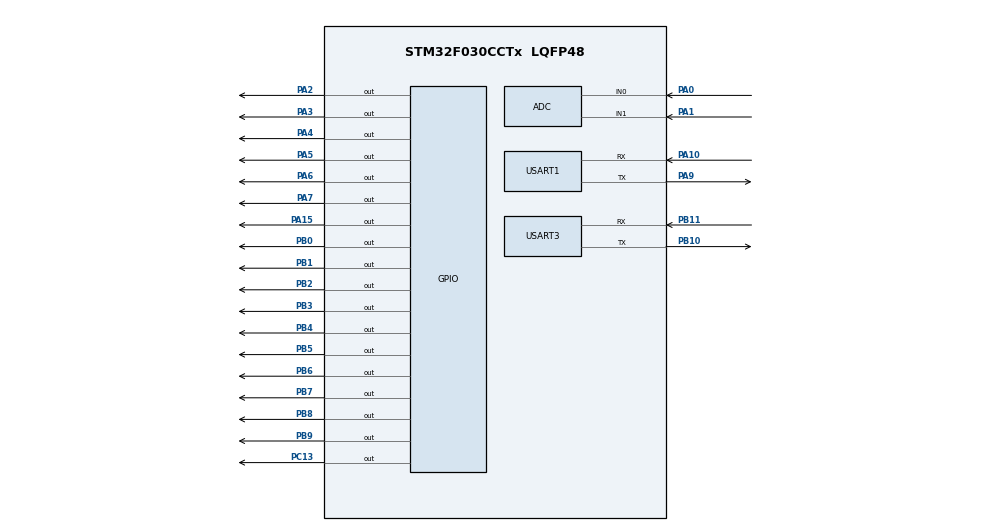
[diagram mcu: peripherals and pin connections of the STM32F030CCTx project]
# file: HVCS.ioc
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Mcu.Family=STM32F0
Mcu.Name=STM32F030CCTx
Mcu.Package=LQFP48
NVIC.ADC1_IRQn=true\:0\:0\:false\:false\:true\:true\:true\:true
NVIC.USART1_IRQn=true\:0\:0\:false\:false\:true\:true\:true\:true
NVIC.USART3_6_IRQn=true\:0\:0\:false\:false\:true\:true\:true\:true
PA0.Mode=IN0
PA0.Signal=ADC_IN0
PA1.Mode=IN1
PA1.Signal=ADC_IN1
PA10.Mode=Asynchronous
PA10.Signal=USART1_RX
PA13.Mode=Serial_Wire
PA13.Signal=SYS_SWDIO
PA14.Mode=Serial_Wire
PA14.Signal=SYS_SWCLK
PA15.Signal=GPIO_Output
PA2.Signal=GPIO_Output
PA3.Signal=GPIO_Output
PA4.Signal=GPIO_Output
PA5.Signal=GPIO_Output
PA6.Signal=GPIO_Output
PA7.Signal=GPIO_Output
PA9.Mode=Asynchronous
PA9.Signal=USART1_TX
PB0.Signal=GPIO_Output
PB1.Signal=GPIO_Output
PB10.Mode=Asynchronous
PB10.Signal=USART3_TX
PB11.Mode=Asynchronous
PB11.Signal=USART3_RX
PB2.Signal=GPIO_Output
PB3.Signal=GPIO_Output
PB4.Signal=GPIO_Output
PB5.Signal=GPIO_Output
PB6.Signal=GPIO_Output
PB7.Signal=GPIO_Output
PB8.Signal=GPIO_Output
PB9.Signal=GPIO_Output
PC13.Signal=GPIO_Output
PF0-OSC_IN.Mode=HSE-External-Oscillator
PF0-OSC_IN.Signal=RCC_OSC_IN
PF1-OSC_OUT.Mode=HSE-External-Oscillator
PF1-OSC_OUT.Signal=RCC_OSC_OUT
ProjectManager.HeapSize=0x200
ProjectManager.StackSize=0x400
ProjectManager.TargetToolchain=CMake
RCC.AHBFreq_Value=32000000
RCC.APB1Freq_Value=32000000
RCC.APB1TimFreq_Value=32000000
RCC.HCLKFreq_Value=32000000
RCC.PLLMUL=RCC_PLL_MUL4
RCC.PLLSourceVirtual=RCC_PLLSOURCE_HSE
RCC.SYSCLKFreq_VALUE=32000000
RCC.SYSCLKSource=RCC_SYSCLKSOURCE_PLLCLK
USART1.VirtualMode-Asynchronous=VM_ASYNC
USART3.VirtualMode-Asynchronous=VM_ASYNC
board=custom

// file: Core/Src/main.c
/* USER CODE BEGIN Header */
/**
  ******************************************************************************
  * @file           : main.c
  * @brief          : Main program body
  ******************************************************************************
  * @attention
  *
  * Copyright (c) 2025 STMicroelectronics.
  * All rights reserved.
  *
  * This software is licensed under terms that can be found in the LICENSE file
  * in the root directory of this software component.
  * If no LICENSE file comes with this software, it is provided AS-IS.
  *
  ******************************************************************************
  */
/* USER CODE END Header */
#include "main.h"

/* USER CODE BEGIN Includes */
#include "app.h"
/* USER CODE END Includes */

void SystemClock_Config(void);
static void MX_GPIO_Init(void);
static void MX_ADC_Init(void);
static void MX_USART1_UART_Init(void);
static void MX_USART3_UART_Init(void);

int main(void)
{

  /* MCU Configuration--------------------------------------------------------*/

  /* Reset of all peripherals, Initializes the Flash interface and the Systick. */
  LL_APB1_GRP2_EnableClock(LL_APB1_GRP2_PERIPH_SYSCFG);
  LL_APB1_GRP1_EnableClock(LL_APB1_GRP1_PERIPH_PWR);

  /* SysTick_IRQn interrupt configuration */
  NVIC_SetPriority(SysTick_IRQn, 3);

  /* Configure the system clock */
  SystemClock_Config();

  /* Initialize all configured peripherals */
  MX_GPIO_Init();
  MX_ADC_Init();
  MX_USART1_UART_Init();
  MX_USART3_UART_Init();
  /* USER CODE BEGIN 2 */
  LL_GPIO_SetOutputPin(V_DIV1_PORT, v_DIV1_PIN);
  LL_GPIO_SetOutputPin(V_DIV2_PORT, v_DIV2_PIN);
  LL_GPIO_SetOutputPin(V_DIV3_PORT, v_DIV3_PIN);
  LL_GPIO_SetOutputPin(V_DIV4_PORT, v_DIV4_PIN);

  App_Main();
  /* USER CODE END 2 */

  /* Infinite loop */
  while (1)
  {

  }
}

void SystemClock_Config(void)
{
  LL_FLASH_SetLatency(LL_FLASH_LATENCY_1);
  while(LL_FLASH_GetLatency() != LL_FLASH_LATENCY_1)
  {
  }
  LL_RCC_HSE_Enable();

   /* Wait till HSE is ready */
  while(LL_RCC_HSE_IsReady() != 1)
  {

  }
  LL_RCC_HSI14_Enable();

   /* Wait till HSI14 is ready */
  while(LL_RCC_HSI14_IsReady() != 1)
  {

  }
  LL_RCC_HSI14_SetCalibTrimming(16);
  LL_RCC_PLL_ConfigDomain_SYS(LL_RCC_PLLSOURCE_HSE, LL_RCC_PLL_MUL_4, LL_RCC_PREDIV_DIV_1);
  LL_RCC_PLL_Enable();

   /* Wait till PLL is ready */
  while(LL_RCC_PLL_IsReady() != 1)
  {

  }
  LL_RCC_SetAHBPrescaler(LL_RCC_SYSCLK_DIV_1);
  LL_RCC_SetAPB1Prescaler(LL_RCC_APB1_DIV_1);
  LL_RCC_SetSysClkSource(LL_RCC_SYS_CLKSOURCE_PLL);

   /* Wait till System clock is ready */
  while(LL_RCC_GetSysClkSource() != LL_RCC_SYS_CLKSOURCE_STATUS_PLL)
  {

  }
  LL_Init1msTick(32000000);
  LL_SetSystemCoreClock(32000000);
  LL_RCC_HSI14_EnableADCControl();
  LL_RCC_SetUSARTClockSource(LL_RCC_USART1_CLKSOURCE_PCLK1);
}

static void MX_ADC_Init(void)
{

  LL_ADC_InitTypeDef ADC_InitStruct = {0};
  LL_ADC_REG_InitTypeDef ADC_REG_InitStruct = {0};

  LL_GPIO_InitTypeDef GPIO_InitStruct = {0};

  /* Peripheral clock enable */
  LL_APB1_GRP2_EnableClock(LL_APB1_GRP2_PERIPH_ADC1);

  LL_AHB1_GRP1_EnableClock(LL_AHB1_GRP1_PERIPH_GPIOA);
  /**ADC GPIO Configuration
  PA0   ------> ADC_IN0
  PA1   ------> ADC_IN1
  */
  GPIO_InitStruct.Pin = LL_GPIO_PIN_0;
  GPIO_InitStruct.Mode = LL_GPIO_MODE_ANALOG;
  GPIO_InitStruct.Pull = LL_GPIO_PULL_NO;
  LL_GPIO_Init(GPIOA, &GPIO_InitStruct);

  GPIO_InitStruct.Pin = LL_GPIO_PIN_1;
  GPIO_InitStruct.Mode = LL_GPIO_MODE_ANALOG;
  GPIO_InitStruct.Pull = LL_GPIO_PULL_NO;
  LL_GPIO_Init(GPIOA, &GPIO_InitStruct);

  /* ADC interrupt Init */
  NVIC_SetPriority(ADC1_IRQn, 0);
  NVIC_EnableIRQ(ADC1_IRQn);

  /** Configure Regular Channel
  */
  LL_ADC_REG_SetSequencerChAdd(ADC1, LL_ADC_CHANNEL_0);

  /** Configure Regular Channel
  */
  LL_ADC_REG_SetSequencerChAdd(ADC1, LL_ADC_CHANNEL_1);

  /** Configure the global features of the ADC (Clock, Resolution, Data Alignment and number of conversion)
  */
  ADC_InitStruct.Clock = LL_ADC_CLOCK_ASYNC;
  ADC_InitStruct.Resolution = LL_ADC_RESOLUTION_12B;
  ADC_InitStruct.DataAlignment = LL_ADC_DATA_ALIGN_RIGHT;
  ADC_InitStruct.LowPowerMode = LL_ADC_LP_MODE_NONE;
  LL_ADC_Init(ADC1, &ADC_InitStruct);
  ADC_REG_InitStruct.TriggerSource = LL_ADC_REG_TRIG_SOFTWARE;
  ADC_REG_InitStruct.SequencerDiscont = LL_ADC_REG_SEQ_DISCONT_DISABLE;
  ADC_REG_InitStruct.ContinuousMode = LL_ADC_REG_CONV_SINGLE;
  ADC_REG_InitStruct.DMATransfer = LL_ADC_REG_DMA_TRANSFER_LIMITED;
  ADC_REG_InitStruct.Overrun = LL_ADC_REG_OVR_DATA_PRESERVED;
  LL_ADC_REG_Init(ADC1, &ADC_REG_InitStruct);
  LL_ADC_REG_SetSequencerScanDirection(ADC1, LL_ADC_REG_SEQ_SCAN_DIR_FORWARD);
  LL_ADC_SetSamplingTimeCommonChannels(ADC1, LL_ADC_SAMPLINGTIME_1CYCLE_5);

}

static void MX_USART1_UART_Init(void)
{

  LL_USART_InitTypeDef USART_InitStruct = {0};

  LL_GPIO_InitTypeDef GPIO_InitStruct = {0};

  /* Peripheral clock enable */
  LL_APB1_GRP2_EnableClock(LL_APB1_GRP2_PERIPH_USART1);

  LL_AHB1_GRP1_EnableClock(LL_AHB1_GRP1_PERIPH_GPIOA);
  /**USART1 GPIO Configuration
  PA9   ------> USART1_TX
  PA10   ------> USART1_RX
  */
  GPIO_InitStruct.Pin = LL_GPIO_PIN_9;
  GPIO_InitStruct.Mode = LL_GPIO_MODE_ALTERNATE;
  GPIO_InitStruct.Speed = LL_GPIO_SPEED_FREQ_HIGH;
  GPIO_InitStruct.OutputType = LL_GPIO_OUTPUT_PUSHPULL;
  GPIO_InitStruct.Pull = LL_GPIO_PULL_NO;
  GPIO_InitStruct.Alternate = LL_GPIO_AF_1;
  LL_GPIO_Init(GPIOA, &GPIO_InitStruct);

  GPIO_InitStruct.Pin = LL_GPIO_PIN_10;
  GPIO_InitStruct.Mode = LL_GPIO_MODE_ALTERNATE;
  GPIO_InitStruct.Speed = LL_GPIO_SPEED_FREQ_HIGH;
  GPIO_InitStruct.OutputType = LL_GPIO_OUTPUT_PUSHPULL;
  GPIO_InitStruct.Pull = LL_GPIO_PULL_NO;
  GPIO_InitStruct.Alternate = LL_GPIO_AF_1;
  LL_GPIO_Init(GPIOA, &GPIO_InitStruct);

  /* USART1 interrupt Init */
  NVIC_SetPriority(USART1_IRQn, 0);
  NVIC_EnableIRQ(USART1_IRQn);

  USART_InitStruct.BaudRate = 115200;
  USART_InitStruct.DataWidth = LL_USART_DATAWIDTH_8B;
  USART_InitStruct.StopBits = LL_USART_STOPBITS_1;
  USART_InitStruct.Parity = LL_USART_PARITY_NONE;
  USART_InitStruct.TransferDirection = LL_USART_DIRECTION_TX_RX;
  USART_InitStruct.HardwareFlowControl = LL_USART_HWCONTROL_NONE;
  USART_InitStruct.OverSampling = LL_USART_OVERSAMPLING_16;
  LL_USART_Init(USART1, &USART_InitStruct);
  LL_USART_DisableIT_CTS(USART1);
  LL_USART_ConfigAsyncMode(USART1);
  LL_USART_Enable(USART1);

}

static void MX_USART3_UART_Init(void)
{

  LL_USART_InitTypeDef USART_InitStruct = {0};

  LL_GPIO_InitTypeDef GPIO_InitStruct = {0};

  /* Peripheral clock enable */
  LL_APB1_GRP1_EnableClock(LL_APB1_GRP1_PERIPH_USART3);

  LL_AHB1_GRP1_EnableClock(LL_AHB1_GRP1_PERIPH_GPIOB);
  /**USART3 GPIO Configuration
  PB10   ------> USART3_TX
  PB11   ------> USART3_RX
  */
  GPIO_InitStruct.Pin = LL_GPIO_PIN_10;
  GPIO_InitStruct.Mode = LL_GPIO_MODE_ALTERNATE;
  GPIO_InitStruct.Speed = LL_GPIO_SPEED_FREQ_HIGH;
  GPIO_InitStruct.OutputType = LL_GPIO_OUTPUT_PUSHPULL;
  GPIO_InitStruct.Pull = LL_GPIO_PULL_NO;
  GPIO_InitStruct.Alternate = LL_GPIO_AF_4;
  LL_GPIO_Init(GPIOB, &GPIO_InitStruct);

  GPIO_InitStruct.Pin = LL_GPIO_PIN_11;
  GPIO_InitStruct.Mode = LL_GPIO_MODE_ALTERNATE;
  GPIO_InitStruct.Speed = LL_GPIO_SPEED_FREQ_HIGH;
  GPIO_InitStruct.OutputType = LL_GPIO_OUTPUT_PUSHPULL;
  GPIO_InitStruct.Pull = LL_GPIO_PULL_NO;
  GPIO_InitStruct.Alternate = LL_GPIO_AF_4;
  LL_GPIO_Init(GPIOB, &GPIO_InitStruct);

  /* USART3 interrupt Init */
  NVIC_SetPriority(USART3_6_IRQn, 0);
  NVIC_EnableIRQ(USART3_6_IRQn);

  USART_InitStruct.BaudRate = 115200;
  USART_InitStruct.DataWidth = LL_USART_DATAWIDTH_8B;
  USART_InitStruct.StopBits = LL_USART_STOPBITS_1;
  USART_InitStruct.Parity = LL_USART_PARITY_NONE;
  USART_InitStruct.TransferDirection = LL_USART_DIRECTION_TX_RX;
  USART_InitStruct.HardwareFlowControl = LL_USART_HWCONTROL_NONE;
  USART_InitStruct.OverSampling = LL_USART_OVERSAMPLING_16;
  LL_USART_Init(USART3, &USART_InitStruct);
  LL_USART_DisableIT_CTS(USART3);
  LL_USART_ConfigAsyncMode(USART3);
  LL_USART_Enable(USART3);

}

static void MX_GPIO_Init(void)
{
  LL_GPIO_InitTypeDef GPIO_InitStruct = {0};

  /* GPIO Ports Clock Enable */
  LL_AHB1_GRP1_EnableClock(LL_AHB1_GRP1_PERIPH_GPIOC);
  LL_AHB1_GRP1_EnableClock(LL_AHB1_GRP1_PERIPH_GPIOF);
  LL_AHB1_GRP1_EnableClock(LL_AHB1_GRP1_PERIPH_GPIOA);
  LL_AHB1_GRP1_EnableClock(LL_AHB1_GRP1_PERIPH_GPIOB);

  /**/
  LL_GPIO_ResetOutputPin(GPIOC, LL_GPIO_PIN_13);

  /**/
  LL_GPIO_ResetOutputPin(GPIOA, LL_GPIO_PIN_2);

  /**/
  LL_GPIO_ResetOutputPin(GPIOA, LL_GPIO_PIN_3);

  /**/
  LL_GPIO_ResetOutputPin(GPIOA, LL_GPIO_PIN_4);

  /**/
  LL_GPIO_ResetOutputPin(GPIOA, LL_GPIO_PIN_5);

  /**/
  LL_GPIO_ResetOutputPin(GPIOA, LL_GPIO_PIN_6);

  /**/
  LL_GPIO_ResetOutputPin(GPIOA, LL_GPIO_PIN_7);

  /**/
  LL_GPIO_ResetOutputPin(GPIOB, LL_GPIO_PIN_0);

  /**/
  LL_GPIO_ResetOutputPin(GPIOB, LL_GPIO_PIN_1);

  /**/
  LL_GPIO_ResetOutputPin(GPIOB, LL_GPIO_PIN_2);

  /**/
  LL_GPIO_ResetOutputPin(GPIOA, LL_GPIO_PIN_15);

  /**/
  LL_GPIO_ResetOutputPin(GPIOB, LL_GPIO_PIN_3);

  /**/
  LL_GPIO_ResetOutputPin(GPIOB, LL_GPIO_PIN_4);

  /**/
  LL_GPIO_ResetOutputPin(GPIOB, LL_GPIO_PIN_5);

  /**/
  LL_GPIO_ResetOutputPin(GPIOB, LL_GPIO_PIN_6);

  /**/
  LL_GPIO_ResetOutputPin(GPIOB, LL_GPIO_PIN_7);

  /**/
  LL_GPIO_ResetOutputPin(GPIOB, LL_GPIO_PIN_8);

  /**/
  LL_GPIO_ResetOutputPin(GPIOB, LL_GPIO_PIN_9);

  /**/
  GPIO_InitStruct.Pin = LL_GPIO_PIN_13;
  GPIO_InitStruct.Mode = LL_GPIO_MODE_OUTPUT;
  GPIO_InitStruct.Speed = LL_GPIO_SPEED_FREQ_LOW;
  GPIO_InitStruct.OutputType = LL_GPIO_OUTPUT_PUSHPULL;
  GPIO_InitStruct.Pull = LL_GPIO_PULL_NO;
  LL_GPIO_Init(GPIOC, &GPIO_InitStruct);

  /**/
  GPIO_InitStruct.Pin = LL_GPIO_PIN_2;
  GPIO_InitStruct.Mode = LL_GPIO_MODE_OUTPUT;
  GPIO_InitStruct.Speed = LL_GPIO_SPEED_FREQ_LOW;
  GPIO_InitStruct.OutputType = LL_GPIO_OUTPUT_PUSHPULL;
  GPIO_InitStruct.Pull = LL_GPIO_PULL_NO;
  LL_GPIO_Init(GPIOA, &GPIO_InitStruct);

  /**/
  GPIO_InitStruct.Pin = LL_GPIO_PIN_3;
  GPIO_InitStruct.Mode = LL_GPIO_MODE_OUTPUT;
  GPIO_InitStruct.Speed = LL_GPIO_SPEED_FREQ_LOW;
  GPIO_InitStruct.OutputType = LL_GPIO_OUTPUT_PUSHPULL;
  GPIO_InitStruct.Pull = LL_GPIO_PULL_NO;
  LL_GPIO_Init(GPIOA, &GPIO_InitStruct);

  /**/
  GPIO_InitStruct.Pin = LL_GPIO_PIN_4;
  GPIO_InitStruct.Mode = LL_GPIO_MODE_OUTPUT;
  GPIO_InitStruct.Speed = LL_GPIO_SPEED_FREQ_LOW;
  GPIO_InitStruct.OutputType = LL_GPIO_OUTPUT_PUSHPULL;
  GPIO_InitStruct.Pull = LL_GPIO_PULL_NO;
  LL_GPIO_Init(GPIOA, &GPIO_InitStruct);

  /**/
  GPIO_InitStruct.Pin = LL_GPIO_PIN_5;
  GPIO_InitStruct.Mode = LL_GPIO_MODE_OUTPUT;
  GPIO_InitStruct.Speed = LL_GPIO_SPEED_FREQ_LOW;
  GPIO_InitStruct.OutputType = LL_GPIO_OUTPUT_PUSHPULL;
  GPIO_InitStruct.Pull = LL_GPIO_PULL_NO;
  LL_GPIO_Init(GPIOA, &GPIO_InitStruct);

  /**/
  GPIO_InitStruct.Pin = LL_GPIO_PIN_6;
  GPIO_InitStruct.Mode = LL_GPIO_MODE_OUTPUT;
  GPIO_InitStruct.Speed = LL_GPIO_SPEED_FREQ_LOW;
  GPIO_InitStruct.OutputType = LL_GPIO_OUTPUT_PUSHPULL;
  GPIO_InitStruct.Pull = LL_GPIO_PULL_NO;
  LL_GPIO_Init(GPIOA, &GPIO_InitStruct);

  /**/
  GPIO_InitStruct.Pin = LL_GPIO_PIN_7;
  GPIO_InitStruct.Mode = LL_GPIO_MODE_OUTPUT;
  GPIO_InitStruct.Speed = LL_GPIO_SPEED_FREQ_LOW;
  GPIO_InitStruct.OutputType = LL_GPIO_OUTPUT_PUSHPULL;
  GPIO_InitStruct.Pull = LL_GPIO_PULL_NO;
  LL_GPIO_Init(GPIOA, &GPIO_InitStruct);

  /**/
  GPIO_InitStruct.Pin = LL_GPIO_PIN_0;
  GPIO_InitStruct.Mode = LL_GPIO_MODE_OUTPUT;
  GPIO_InitStruct.Speed = LL_GPIO_SPEED_FREQ_LOW;
  GPIO_InitStruct.OutputType = LL_GPIO_OUTPUT_PUSHPULL;
  GPIO_InitStruct.Pull = LL_GPIO_PULL_NO;
  LL_GPIO_Init(GPIOB, &GPIO_InitStruct);

  /**/
  GPIO_InitStruct.Pin = LL_GPIO_PIN_1;
  GPIO_InitStruct.Mode = LL_GPIO_MODE_OUTPUT;
  GPIO_InitStruct.Speed = LL_GPIO_SPEED_FREQ_LOW;
  GPIO_InitStruct.OutputType = LL_GPIO_OUTPUT_PUSHPULL;
  GPIO_InitStruct.Pull = LL_GPIO_PULL_NO;
  LL_GPIO_Init(GPIOB, &GPIO_InitStruct);

  /**/
  GPIO_InitStruct.Pin = LL_GPIO_PIN_2;
  GPIO_InitStruct.Mode = LL_GPIO_MODE_OUTPUT;
  GPIO_InitStruct.Speed = LL_GPIO_SPEED_FREQ_LOW;
  GPIO_InitStruct.OutputType = LL_GPIO_OUTPUT_PUSHPULL;
  GPIO_InitStruct.Pull = LL_GPIO_PULL_NO;
  LL_GPIO_Init(GPIOB, &GPIO_InitStruct);

  /**/
  GPIO_InitStruct.Pin = LL_GPIO_PIN_15;
  GPIO_InitStruct.Mode = LL_GPIO_MODE_OUTPUT;
  GPIO_InitStruct.Speed = LL_GPIO_SPEED_FREQ_LOW;
  GPIO_InitStruct.OutputType = LL_GPIO_OUTPUT_PUSHPULL;
  GPIO_InitStruct.Pull = LL_GPIO_PULL_NO;
  LL_GPIO_Init(GPIOA, &GPIO_InitStruct);

  /**/
  GPIO_InitStruct.Pin = LL_GPIO_PIN_3;
  GPIO_InitStruct.Mode = LL_GPIO_MODE_OUTPUT;
  GPIO_InitStruct.Speed = LL_GPIO_SPEED_FREQ_LOW;
  GPIO_InitStruct.OutputType = LL_GPIO_OUTPUT_PUSHPULL;
  GPIO_InitStruct.Pull = LL_GPIO_PULL_NO;
  LL_GPIO_Init(GPIOB, &GPIO_InitStruct);

  /**/
  GPIO_InitStruct.Pin = LL_GPIO_PIN_4;
  GPIO_InitStruct.Mode = LL_GPIO_MODE_OUTPUT;
  GPIO_InitStruct.Speed = LL_GPIO_SPEED_FREQ_LOW;
  GPIO_InitStruct.OutputType = LL_GPIO_OUTPUT_PUSHPULL;
  GPIO_InitStruct.Pull = LL_GPIO_PULL_NO;
  LL_GPIO_Init(GPIOB, &GPIO_InitStruct);

  /**/
  GPIO_InitStruct.Pin = LL_GPIO_PIN_5;
  GPIO_InitStruct.Mode = LL_GPIO_MODE_OUTPUT;
  GPIO_InitStruct.Speed = LL_GPIO_SPEED_FREQ_LOW;
  GPIO_InitStruct.OutputType = LL_GPIO_OUTPUT_PUSHPULL;
  GPIO_InitStruct.Pull = LL_GPIO_PULL_NO;
  LL_GPIO_Init(GPIOB, &GPIO_InitStruct);

  /**/
  GPIO_InitStruct.Pin = LL_GPIO_PIN_6;
  GPIO_InitStruct.Mode = LL_GPIO_MODE_OUTPUT;
  GPIO_InitStruct.Speed = LL_GPIO_SPEED_FREQ_LOW;
  GPIO_InitStruct.OutputType = LL_GPIO_OUTPUT_PUSHPULL;
  GPIO_InitStruct.Pull = LL_GPIO_PULL_NO;
  LL_GPIO_Init(GPIOB, &GPIO_InitStruct);

  /**/
  GPIO_InitStruct.Pin = LL_GPIO_PIN_7;
  GPIO_InitStruct.Mode = LL_GPIO_MODE_OUTPUT;
  GPIO_InitStruct.Speed = LL_GPIO_SPEED_FREQ_LOW;
  GPIO_InitStruct.OutputType = LL_GPIO_OUTPUT_PUSHPULL;
  GPIO_InitStruct.Pull = LL_GPIO_PULL_NO;
  LL_GPIO_Init(GPIOB, &GPIO_InitStruct);

  /**/
  GPIO_InitStruct.Pin = LL_GPIO_PIN_8;
  GPIO_InitStruct.Mode = LL_GPIO_MODE_OUTPUT;
  GPIO_InitStruct.Speed = LL_GPIO_SPEED_FREQ_LOW;
  GPIO_InitStruct.OutputType = LL_GPIO_OUTPUT_PUSHPULL;
  GPIO_InitStruct.Pull = LL_GPIO_PULL_NO;
  LL_GPIO_Init(GPIOB, &GPIO_InitStruct);

  /**/
  GPIO_InitStruct.Pin = LL_GPIO_PIN_9;
  GPIO_InitStruct.Mode = LL_GPIO_MODE_OUTPUT;
  GPIO_InitStruct.Speed = LL_GPIO_SPEED_FREQ_LOW;
  GPIO_InitStruct.OutputType = LL_GPIO_OUTPUT_PUSHPULL;
  GPIO_InitStruct.Pull = LL_GPIO_PULL_NO;
  LL_GPIO_Init(GPIOB, &GPIO_InitStruct);

}

void Error_Handler(void)
{
  __disable_irq();
  while (1)
  {
  }
}
